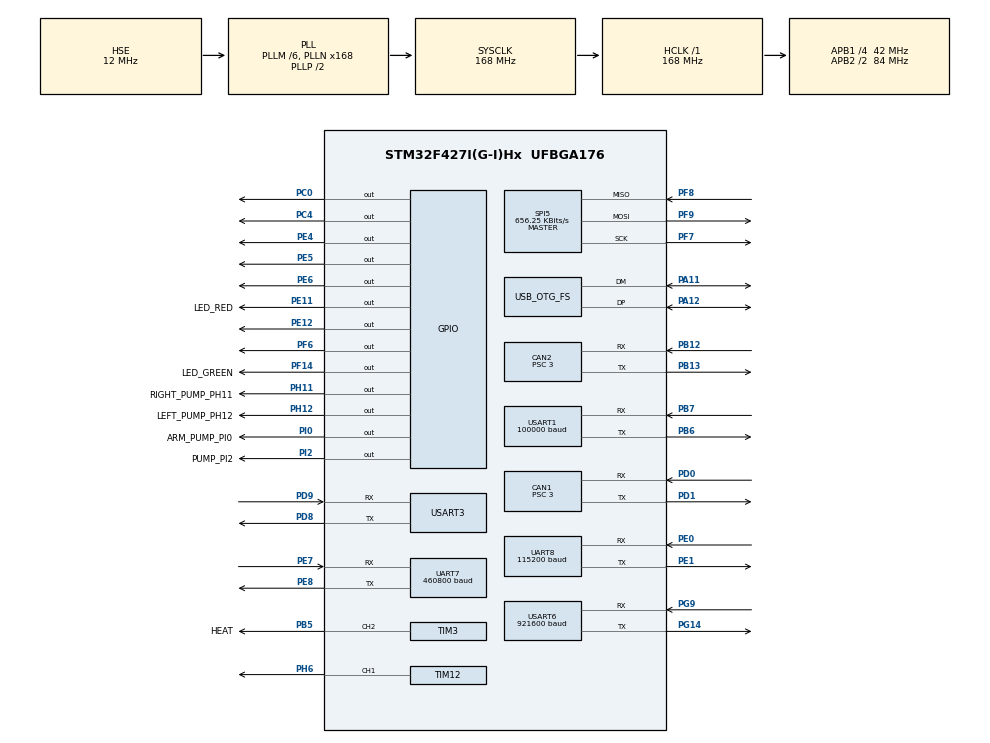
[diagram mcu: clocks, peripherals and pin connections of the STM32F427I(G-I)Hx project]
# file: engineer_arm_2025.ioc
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CAN1.ABOM=ENABLE
CAN1.AWUM=ENABLE
CAN1.BS1=CAN_BS1_7TQ
CAN1.BS2=CAN_BS2_6TQ
CAN1.CalculateBaudRate=1000000
CAN1.CalculateTimeBit=1000
CAN1.CalculateTimeQuantum=71.42857142857143
CAN1.NART=ENABLE
CAN1.Prescaler=3
CAN1.RFLM=DISABLE
CAN1.TXFP=ENABLE
CAN2.ABOM=ENABLE
CAN2.AWUM=ENABLE
CAN2.BS1=CAN_BS1_7TQ
CAN2.BS2=CAN_BS2_6TQ
CAN2.CalculateBaudRate=1000000
CAN2.CalculateTimeBit=1000
CAN2.CalculateTimeQuantum=71.42857142857143
CAN2.NART=ENABLE
CAN2.Prescaler=3
CAN2.TXFP=ENABLE
Dma.Request0=USART1_RX
Dma.Request1=SPI5_RX
Dma.Request2=SPI5_TX
Dma.Request3=UART8_RX
Dma.Request4=UART8_TX
Dma.Request5=USART3_RX
Dma.Request6=USART3_TX
Dma.Request7=UART7_RX
Dma.Request8=USART6_RX
Dma.Request9=USART6_TX
Dma.SPI5_RX.1.Direction=DMA_PERIPH_TO_MEMORY
Dma.SPI5_RX.1.FIFOMode=DMA_FIFOMODE_DISABLE
Dma.SPI5_RX.1.Instance=DMA2_Stream3
Dma.SPI5_RX.1.MemDataAlignment=DMA_MDATAALIGN_BYTE
Dma.SPI5_RX.1.MemInc=DMA_MINC_ENABLE
Dma.SPI5_RX.1.Mode=DMA_NORMAL
Dma.SPI5_RX.1.PeriphDataAlignment=DMA_PDATAALIGN_BYTE
Dma.SPI5_RX.1.PeriphInc=DMA_PINC_DISABLE
Dma.SPI5_RX.1.Priority=DMA_PRIORITY_HIGH
Dma.SPI5_TX.2.Direction=DMA_MEMORY_TO_PERIPH
Dma.SPI5_TX.2.FIFOMode=DMA_FIFOMODE_DISABLE
Dma.SPI5_TX.2.Instance=DMA2_Stream4
Dma.SPI5_TX.2.MemDataAlignment=DMA_MDATAALIGN_BYTE
Dma.SPI5_TX.2.MemInc=DMA_MINC_ENABLE
Dma.SPI5_TX.2.Mode=DMA_NORMAL
Dma.SPI5_TX.2.PeriphDataAlignment=DMA_PDATAALIGN_BYTE
Dma.SPI5_TX.2.PeriphInc=DMA_PINC_DISABLE
Dma.SPI5_TX.2.Priority=DMA_PRIORITY_HIGH
Dma.UART7_RX.7.Direction=DMA_PERIPH_TO_MEMORY
Dma.UART7_RX.7.FIFOMode=DMA_FIFOMODE_DISABLE
Dma.UART7_RX.7.Instance=DMA1_Stream3
Dma.UART7_RX.7.MemDataAlignment=DMA_MDATAALIGN_BYTE
Dma.UART7_RX.7.MemInc=DMA_MINC_ENABLE
Dma.UART7_RX.7.Mode=DMA_NORMAL
Dma.UART7_RX.7.PeriphDataAlignment=DMA_PDATAALIGN_BYTE
Dma.UART7_RX.7.PeriphInc=DMA_PINC_DISABLE
Dma.UART7_RX.7.Priority=DMA_PRIORITY_HIGH
Dma.UART8_RX.3.Direction=DMA_PERIPH_TO_MEMORY
Dma.UART8_RX.3.FIFOMode=DMA_FIFOMODE_DISABLE
Dma.UART8_RX.3.Instance=DMA1_Stream6
Dma.UART8_RX.3.MemDataAlignment=DMA_MDATAALIGN_BYTE
Dma.UART8_RX.3.MemInc=DMA_MINC_ENABLE
Dma.UART8_RX.3.Mode=DMA_CIRCULAR
Dma.UART8_RX.3.PeriphDataAlignment=DMA_PDATAALIGN_BYTE
Dma.UART8_RX.3.PeriphInc=DMA_PINC_DISABLE
Dma.UART8_RX.3.Priority=DMA_PRIORITY_HIGH
Dma.UART8_TX.4.Direction=DMA_MEMORY_TO_PERIPH
Dma.UART8_TX.4.FIFOMode=DMA_FIFOMODE_DISABLE
Dma.UART8_TX.4.Instance=DMA1_Stream0
Dma.UART8_TX.4.MemDataAlignment=DMA_MDATAALIGN_BYTE
Dma.UART8_TX.4.MemInc=DMA_MINC_ENABLE
Dma.UART8_TX.4.Mode=DMA_NORMAL
Dma.UART8_TX.4.PeriphDataAlignment=DMA_PDATAALIGN_BYTE
Dma.UART8_TX.4.PeriphInc=DMA_PINC_DISABLE
Dma.UART8_TX.4.Priority=DMA_PRIORITY_HIGH
Dma.USART1_RX.0.Direction=DMA_PERIPH_TO_MEMORY
Dma.USART1_RX.0.FIFOMode=DMA_FIFOMODE_DISABLE
Dma.USART1_RX.0.Instance=DMA2_Stream2
Dma.USART1_RX.0.MemDataAlignment=DMA_MDATAALIGN_BYTE
Dma.USART1_RX.0.MemInc=DMA_MINC_ENABLE
Dma.USART1_RX.0.Mode=DMA_NORMAL
Dma.USART1_RX.0.PeriphDataAlignment=DMA_PDATAALIGN_BYTE
Dma.USART1_RX.0.PeriphInc=DMA_PINC_DISABLE
Dma.USART1_RX.0.Priority=DMA_PRIORITY_HIGH
Dma.USART3_RX.5.Direction=DMA_PERIPH_TO_MEMORY
Dma.USART3_RX.5.FIFOMode=DMA_FIFOMODE_DISABLE
Dma.USART3_RX.5.Instance=DMA1_Stream1
Dma.USART3_RX.5.MemDataAlignment=DMA_MDATAALIGN_BYTE
Dma.USART3_RX.5.MemInc=DMA_MINC_ENABLE
Dma.USART3_RX.5.Mode=DMA_CIRCULAR
Dma.USART3_RX.5.PeriphDataAlignment=DMA_PDATAALIGN_BYTE
Dma.USART3_RX.5.PeriphInc=DMA_PINC_DISABLE
Dma.USART3_RX.5.Priority=DMA_PRIORITY_HIGH
Dma.USART3_TX.6.Direction=DMA_MEMORY_TO_PERIPH
Dma.USART3_TX.6.FIFOMode=DMA_FIFOMODE_DISABLE
Dma.USART3_TX.6.Instance=DMA1_Stream4
Dma.USART3_TX.6.MemDataAlignment=DMA_MDATAALIGN_BYTE
Dma.USART3_TX.6.MemInc=DMA_MINC_ENABLE
Dma.USART3_TX.6.Mode=DMA_NORMAL
Dma.USART3_TX.6.PeriphDataAlignment=DMA_PDATAALIGN_BYTE
Dma.USART3_TX.6.PeriphInc=DMA_PINC_DISABLE
Dma.USART3_TX.6.Priority=DMA_PRIORITY_HIGH
Dma.USART6_RX.8.Direction=DMA_PERIPH_TO_MEMORY
Dma.USART6_RX.8.FIFOMode=DMA_FIFOMODE_DISABLE
Dma.USART6_RX.8.Instance=DMA2_Stream1
Dma.USART6_RX.8.MemDataAlignment=DMA_MDATAALIGN_BYTE
Dma.USART6_RX.8.MemInc=DMA_MINC_ENABLE
Dma.USART6_RX.8.Mode=DMA_CIRCULAR
Dma.USART6_RX.8.PeriphDataAlignment=DMA_PDATAALIGN_BYTE
Dma.USART6_RX.8.PeriphInc=DMA_PINC_DISABLE
Dma.USART6_RX.8.Priority=DMA_PRIORITY_HIGH
Dma.USART6_TX.9.Direction=DMA_MEMORY_TO_PERIPH
Dma.USART6_TX.9.FIFOMode=DMA_FIFOMODE_DISABLE
Dma.USART6_TX.9.Instance=DMA2_Stream6
Dma.USART6_TX.9.MemDataAlignment=DMA_MDATAALIGN_BYTE
Dma.USART6_TX.9.MemInc=DMA_MINC_ENABLE
Dma.USART6_TX.9.Mode=DMA_NORMAL
Dma.USART6_TX.9.PeriphDataAlignment=DMA_PDATAALIGN_BYTE
Dma.USART6_TX.9.PeriphInc=DMA_PINC_DISABLE
Dma.USART6_TX.9.Priority=DMA_PRIORITY_HIGH
FREERTOS.BinarySemaphores01=ArmMotor1UpdateBinarySem,Dynamic,NULL,Depleted;ArmMotor2UpdateBinarySem,Dynamic,NULL,Depleted;ArmMotor3UpdateBinarySem,Dynamic,NULL,Depleted;ArmMotor4UpdateBinarySem,Dynamic,NULL,Depleted;ArmMotor5UpdateBinarySem,Dynamic,NULL,Depleted;ArmMotor6UpdateBinarySem,Dynamic,NULL,Depleted;RCUpdateBinarySem,Dynamic,NULL,Depleted;PCUpdateBinarySem,Dynamic,NULL,Depleted;CustomBinarySem,Dynamic,NULL,Depleted;judgementInitBinarySem,Dynamic,NULL,Depleted;customRxBinarySem,Dynamic,NULL,Depleted;CommunicateUpdateBinarySem,Dynamic,NULL,Depleted;IMUUpdateBinarySem,Dynamic,NULL,Depleted;servoctrlTxBinarySem,Dynamic,NULL,Available;hi229umRxBinarySem,Dynamic,NULL,Depleted;VTRCUpdateBinarySem,Dynamic,NULL,Depleted
FREERTOS.CountingSemaphores01=CAN1CountingSem,3,Dynamic,NULL,3;CAN2CountingSem,3,Dynamic,NULL,3
FREERTOS.Events01=refereeEvent,Dynamic,NULL;RefereeEvent,Dynamic,NULL
FREERTOS.INCLUDE_xEventGroupSetBitFromISR=1
FREERTOS.Queues01=CAN1SendQueue,32,can_device_transmit_member,0,Dynamic,NULL,NULL;CAN2SendQueue,16,can_device_transmit_member,0,Dynamic,NULL,NULL;ServoCtrlQueue,16,servo_ctrl_data_t,0,Dynamic,NULL,NULL
FREERTOS.Tasks01=defaultTask,24,128,StartDefaultTask,Default,NULL,Dynamic,NULL,NULL;CAN1SendTask,40,128,CAN1Send_Task,As weak,NULL,Dynamic,NULL,NULL;CAN2SendTask,40,128,CAN2Send_Task,As weak,NULL,Dynamic,NULL,NULL;armtask,24,512,arm_task,As weak,NULL,Dynamic,NULL,NULL;lostchecktask,24,512,lost_check_task,As weak,NULL,Dynamic,NULL,NULL;rctask,24,256,rc_task,As weak,NULL,Dynamic,NULL,NULL;pc_receivetask,47,1024,pc_receive_task,As weak,NULL,Dynamic,NULL,NULL;pc_transmittask,47,1024,pc_transmit_task,As weak,NULL,Dynamic,NULL,NULL;receiveCtrltask,24,256,receiveCtrl_task,As weak,NULL,Dynamic,NULL,NULL;updateUIDatatas,24,512,updateUIData_task,As weak,NULL,Dynamic,NULL,NULL;judgeCtrltask,24,256,judgeCtrl_task,As weak,NULL,Dynamic,NULL,NULL;controllertask,24,256,controller_task,As weak,NULL,Dynamic,NULL,NULL;imutask,24,256,imu_task,As weak,NULL,Dynamic,NULL,NULL;communicatetask,24,256,communicate_task,As weak,NULL,Dynamic,NULL,NULL;servo_ctrltask,24,128,servo_ctrl_task,As weak,NULL,Dynamic,NULL,NULL;gimbaltask,24,256,gimbal_task,As weak,NULL,Dynamic,NULL,NULL;hi229umtask,24,256,hi229um_task,As weak,NULL,Dynamic,NULL,NULL;arm_resettask,24,256,arm_reset_task,As weak,NULL,Dynamic,NULL,NULL;self_ctrltask,24,256,self_ctrl_task,As weak,NULL,Dynamic,NULL,NULL;self_kb_stateta,24,256,self_kb_state_task,As weak,NULL,Dynamic,NULL,NULL;self_kb_eventta,24,256,self_kb_event_task,As weak,NULL,Dynamic,NULL,NULL;VT_rctask,24,256,VT_rc_task,As weak,NULL,Dynamic,NULL,NULL
FREERTOS.configTOTAL_HEAP_SIZE=120000
FREERTOS.configUSE_NEWLIB_REENTRANT=1
IWDG.Prescaler=IWDG_PRESCALER_64
IWDG.Reload=625
Mcu.Family=STM32F4
Mcu.Name=STM32F427I(G-I)Hx
Mcu.Package=UFBGA176
NVIC.CAN1_RX0_IRQn=true\:5\:0\:false\:false\:true\:true\:true\:true\:true
NVIC.CAN1_TX_IRQn=true\:5\:0\:false\:false\:true\:true\:true\:true\:true
NVIC.CAN2_RX1_IRQn=true\:5\:0\:false\:false\:true\:true\:true\:true\:true
NVIC.CAN2_TX_IRQn=true\:5\:0\:false\:false\:true\:true\:true\:true\:true
NVIC.DMA1_Stream0_IRQn=true\:5\:0\:false\:false\:true\:true\:false\:true\:true
NVIC.DMA1_Stream1_IRQn=true\:5\:0\:false\:false\:true\:true\:false\:true\:true
NVIC.DMA1_Stream3_IRQn=true\:5\:0\:false\:false\:true\:true\:false\:true\:true
NVIC.DMA1_Stream4_IRQn=true\:5\:0\:false\:false\:true\:true\:false\:true\:true
NVIC.DMA1_Stream6_IRQn=true\:5\:0\:false\:false\:true\:true\:false\:true\:true
NVIC.DMA2_Stream1_IRQn=true\:5\:0\:false\:false\:true\:true\:false\:true\:true
NVIC.DMA2_Stream2_IRQn=true\:5\:0\:false\:false\:true\:true\:false\:true\:true
NVIC.DMA2_Stream3_IRQn=true\:5\:0\:false\:false\:true\:true\:false\:true\:true
NVIC.DMA2_Stream4_IRQn=true\:5\:0\:false\:false\:true\:true\:false\:true\:true
NVIC.DMA2_Stream6_IRQn=true\:5\:0\:false\:false\:true\:true\:false\:true\:true
NVIC.OTG_FS_IRQn=true\:5\:0\:false\:false\:true\:true\:true\:true\:true
NVIC.PriorityGroup=NVIC_PRIORITYGROUP_4
NVIC.SPI5_IRQn=true\:5\:0\:false\:false\:true\:true\:true\:true\:true
NVIC.TIM7_IRQn=true\:0\:0\:true\:false\:true\:false\:false\:true\:true
NVIC.TimeBase=TIM7_IRQn
NVIC.TimeBaseIP=TIM7
NVIC.UART7_IRQn=true\:5\:0\:false\:false\:true\:true\:true\:true\:true
NVIC.UART8_IRQn=true\:5\:0\:false\:false\:true\:true\:true\:true\:true
NVIC.USART1_IRQn=true\:5\:0\:false\:false\:true\:true\:true\:true\:true
NVIC.USART3_IRQn=true\:5\:0\:false\:false\:true\:true\:true\:true\:true
NVIC.USART6_IRQn=true\:5\:0\:false\:false\:true\:true\:true\:true\:true
PA11.Mode=Device_Only
PA11.Signal=USB_OTG_FS_DM
PA12.Mode=Device_Only
PA12.Signal=USB_OTG_FS_DP
PA13.Mode=Serial_Wire
PA13.Signal=SYS_JTMS-SWDIO
PA14.Mode=Serial_Wire
PA14.Signal=SYS_JTCK-SWCLK
PB12.Mode=CAN_Activate
PB12.Signal=CAN2_RX
PB13.Mode=CAN_Activate
PB13.Signal=CAN2_TX
PB5.GPIO_Label=HEAT
PB5.GPIO_PuPd=GPIO_PULLUP
PB5.GPIO_Speed=GPIO_SPEED_FREQ_HIGH
PB5.Signal=S_TIM3_CH2
PB6.Mode=Asynchronous
PB6.Signal=USART1_TX
PB7.Mode=Asynchronous
PB7.Signal=USART1_RX
PC0.GPIO_ModeDefaultOutputPP=GPIO_MODE_OUTPUT_OD
PC0.GPIO_PuPd=GPIO_PULLUP
PC0.GPIO_Speed=GPIO_SPEED_FREQ_HIGH
PC0.Signal=GPIO_Output
PC4.GPIO_ModeDefaultOutputPP=GPIO_MODE_OUTPUT_OD
PC4.GPIO_PuPd=GPIO_PULLUP
PC4.GPIO_Speed=GPIO_SPEED_FREQ_HIGH
PC4.Signal=GPIO_Output
PD0.Mode=CAN_Activate
PD0.Signal=CAN1_RX
PD1.Mode=CAN_Activate
PD1.Signal=CAN1_TX
PD8.Mode=Asynchronous
PD8.Signal=USART3_TX
PD9.Mode=Asynchronous
PD9.Signal=USART3_RX
PE0.Mode=Asynchronous
PE0.Signal=UART8_RX
PE1.Mode=Asynchronous
PE1.Signal=UART8_TX
PE11.GPIO_Label=LED_RED
PE11.PinState=GPIO_PIN_SET
PE11.Signal=GPIO_Output
PE12.GPIO_ModeDefaultOutputPP=GPIO_MODE_OUTPUT_OD
PE12.GPIO_PuPd=GPIO_PULLUP
PE12.GPIO_Speed=GPIO_SPEED_FREQ_HIGH
PE12.Signal=GPIO_Output
PE4.GPIO_ModeDefaultOutputPP=GPIO_MODE_OUTPUT_OD
PE4.GPIO_PuPd=GPIO_PULLUP
PE4.GPIO_Speed=GPIO_SPEED_FREQ_HIGH
PE4.Signal=GPIO_Output
PE5.GPIO_ModeDefaultOutputPP=GPIO_MODE_OUTPUT_OD
PE5.GPIO_PuPd=GPIO_PULLUP
PE5.GPIO_Speed=GPIO_SPEED_FREQ_HIGH
PE5.Signal=GPIO_Output
PE6.GPIO_ModeDefaultOutputPP=GPIO_MODE_OUTPUT_OD
PE6.GPIO_PuPd=GPIO_PULLUP
PE6.GPIO_Speed=GPIO_SPEED_FREQ_HIGH
PE6.Signal=GPIO_Output
PE7.Mode=Asynchronous
PE7.Signal=UART7_RX
PE8.Mode=Asynchronous
PE8.Signal=UART7_TX
PF14.GPIO_Label=LED_GREEN
PF14.PinState=GPIO_PIN_RESET
PF14.Signal=GPIO_Output
PF6.Signal=GPIO_Output
PF7.Mode=Full_Duplex_Master
PF7.Signal=SPI5_SCK
PF8.Mode=Full_Duplex_Master
PF8.Signal=SPI5_MISO
PF9.Mode=Full_Duplex_Master
PF9.Signal=SPI5_MOSI
PG14.Mode=Asynchronous
PG14.Signal=USART6_TX
PG9.Mode=Asynchronous
PG9.Signal=USART6_RX
PH0/OSC_IN.Mode=HSE-External-Oscillator
PH0/OSC_IN.Signal=RCC_OSC_IN
PH1/OSC_OUT.Mode=HSE-External-Oscillator
PH1/OSC_OUT.Signal=RCC_OSC_OUT
PH11.GPIO_Label=RIGHT_PUMP_PH11
PH11.GPIO_Speed=GPIO_SPEED_FREQ_HIGH
PH11.Signal=GPIO_Output
PH12.GPIO_Label=LEFT_PUMP_PH12
PH12.GPIO_Speed=GPIO_SPEED_FREQ_HIGH
PH12.Signal=GPIO_Output
PH6.Signal=S_TIM12_CH1
PI0.GPIO_Label=ARM_PUMP_PI0
PI0.PinState=GPIO_PIN_RESET
PI0.Signal=GPIO_Output
PI2.GPIO_Label=PUMP_PI2
PI2.PinState=GPIO_PIN_RESET
PI2.Signal=GPIO_Output
ProjectManager.HeapSize=0x1000
ProjectManager.StackSize=0x1000
ProjectManager.TargetToolchain=STM32CubeIDE
RCC.48MHZClocksFreq_Value=48000000
RCC.AHBFreq_Value=168000000
RCC.APB1CLKDivider=RCC_HCLK_DIV4
RCC.APB1Freq_Value=42000000
RCC.APB1TimFreq_Value=84000000
RCC.APB2CLKDivider=RCC_HCLK_DIV2
RCC.APB2Freq_Value=84000000
RCC.APB2TimFreq_Value=168000000
RCC.CortexFreq_Value=168000000
RCC.HCLKFreq_Value=168000000
RCC.HSE_VALUE=12000000
RCC.HSI_VALUE=16000000
RCC.LSE_VALUE=32768
RCC.PLLM=6
RCC.PLLN=168
RCC.PLLQ=7
RCC.SYSCLKFreq_VALUE=168000000
RCC.SYSCLKSource=RCC_SYSCLKSOURCE_PLLCLK
RCC.VCOOutputFreq_Value=336000000
SH.S_TIM12_CH1.0=TIM12_CH1,PWM Generation1 CH1
SH.S_TIM3_CH2.0=TIM3_CH2,PWM Generation2 CH2
SPI5.BaudRatePrescaler=SPI_BAUDRATEPRESCALER_128
SPI5.CalculateBaudRate=656.25 KBits/s
SPI5.Direction=SPI_DIRECTION_2LINES
SPI5.Mode=SPI_MODE_MASTER
SPI5.VirtualType=VM_MASTER
STMicroelectronics.X-CUBE-ALGOBUILD.1.3.0.LibraryCcDSPOoLibraryJjDSPOoLibrary=true
TIM12.Channel-PWM\ Generation1\ CH1=TIM_CHANNEL_1
TIM12.Period=370-1
TIM12.Prescaler=84-1
TIM3.Channel-PWM\ Generation2\ CH2=TIM_CHANNEL_2
TIM3.Period=9999
UART7.BaudRate=460800
UART7.VirtualMode=Asynchronous
UART8.BaudRate=115200
UART8.VirtualMode=Asynchronous
UART8.WordLength=WORDLENGTH_8B
USART1.BaudRate=100000
USART1.Parity=PARITY_EVEN
USART1.VirtualMode=VM_ASYNC
USART1.WordLength=WORDLENGTH_9B
USART3.VirtualMode=VM_ASYNC
USART3.WordLength=WORDLENGTH_8B
USART6.BaudRate=921600
USART6.VirtualMode=VM_ASYNC
USB_DEVICE.APP_RX_DATA_SIZE-CDC_FS=2048
USB_DEVICE.APP_TX_DATA_SIZE-CDC_FS=2048
USB_DEVICE.CLASS_NAME_FS=CDC
USB_DEVICE.VirtualMode-CDC_FS=Cdc
USB_DEVICE.VirtualModeFS=Cdc_FS
USB_OTG_FS.VirtualMode=Device_Only
VP_FREERTOS_VS_CMSIS_V2.Mode=CMSIS_V2
VP_IWDG_VS_IWDG.Mode=IWDG_Activate
VP_STMicroelectronics.X-CUBE-ALGOBUILD_VS_DSPOoLibraryJjLibrary_1.3.0_1.3.0.Mode=DSPOoLibraryJjLibrary
VP_SYS_VS_tim7.Mode=TIM7
VP_TIM12_VS_ClockSourceINT.Mode=Internal
VP_TIM3_VS_ClockSourceINT.Mode=Internal
VP_USB_DEVICE_VS_USB_DEVICE_CDC_FS.Mode=CDC_FS
board=custom

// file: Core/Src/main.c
/* USER CODE BEGIN Header */
/**
  ******************************************************************************
  * @file           : main.c
  * @brief          : Main program body
  ******************************************************************************
  * @attention
  *
  * Copyright (c) 2025 STMicroelectronics.
  * All rights reserved.
  *
  * This software is licensed under terms that can be found in the LICENSE file
  * in the root directory of this software component.
  * If no LICENSE file comes with this software, it is provided AS-IS.
  *
  ******************************************************************************
  */
/* USER CODE END Header */
#include "main.h"
#include "cmsis_os.h"
#include "can.h"
#include "dma.h"
#include "iwdg.h"
#include "spi.h"
#include "tim.h"
#include "usart.h"
#include "usb_device.h"
#include "gpio.h"

/* USER CODE BEGIN Includes */
#include "compatible.h"
#include "bsp_dwt.h"
/* USER CODE END Includes */

void SystemClock_Config(void);
void MX_FREERTOS_Init(void);

int main(void)
{

  /* USER CODE BEGIN 1 */
    __HAL_RCC_SYSCLK_CONFIG(RCC_SYSCLKSOURCE_HSI);
  /* USER CODE END 1 */

  /* MCU Configuration--------------------------------------------------------*/

  /* Reset of all peripherals, Initializes the Flash interface and the Systick. */
  HAL_Init();

  /* Configure the system clock */
  SystemClock_Config();

  /* Initialize all configured peripherals */
  MX_GPIO_Init();
  MX_DMA_Init();
  MX_SPI5_Init();
  MX_USART1_UART_Init();
  MX_CAN1_Init();
  MX_CAN2_Init();
  MX_TIM12_Init();
  MX_UART8_Init();
  MX_TIM3_Init();
  MX_USART3_UART_Init();
  MX_UART7_Init();
  MX_USART6_UART_Init();
  MX_IWDG_Init();
  /* USER CODE BEGIN 2 */
    DWT_Init(168);
    bsp_can_init();
  /* USER CODE END 2 */

  /* Init scheduler */
  osKernelInitialize();

  /* Call init function for freertos objects (in cmsis_os2.c) */
  MX_FREERTOS_Init();

  /* Start scheduler */
  osKernelStart();

  /* We should never get here as control is now taken by the scheduler */

  /* Infinite loop */
  while (1)
  {

  }
}

void SystemClock_Config(void)
{
  RCC_OscInitTypeDef RCC_OscInitStruct = {0};
  RCC_ClkInitTypeDef RCC_ClkInitStruct = {0};

  /** Configure the main internal regulator output voltage
  */
  __HAL_RCC_PWR_CLK_ENABLE();
  __HAL_PWR_VOLTAGESCALING_CONFIG(PWR_REGULATOR_VOLTAGE_SCALE1);

  /** Initializes the RCC Oscillators according to the specified parameters
  * in the RCC_OscInitTypeDef structure.
  */
  RCC_OscInitStruct.OscillatorType = RCC_OSCILLATORTYPE_LSI|RCC_OSCILLATORTYPE_HSE;
  RCC_OscInitStruct.HSEState = RCC_HSE_ON;
  RCC_OscInitStruct.LSIState = RCC_LSI_ON;
  RCC_OscInitStruct.PLL.PLLState = RCC_PLL_ON;
  RCC_OscInitStruct.PLL.PLLSource = RCC_PLLSOURCE_HSE;
  RCC_OscInitStruct.PLL.PLLM = 6;
  RCC_OscInitStruct.PLL.PLLN = 168;
  RCC_OscInitStruct.PLL.PLLP = RCC_PLLP_DIV2;
  RCC_OscInitStruct.PLL.PLLQ = 7;
  if (HAL_RCC_OscConfig(&RCC_OscInitStruct) != HAL_OK)
  {
    Error_Handler();
  }

  /** Initializes the CPU, AHB and APB buses clocks
  */
  RCC_ClkInitStruct.ClockType = RCC_CLOCKTYPE_HCLK|RCC_CLOCKTYPE_SYSCLK
                              |RCC_CLOCKTYPE_PCLK1|RCC_CLOCKTYPE_PCLK2;
  RCC_ClkInitStruct.SYSCLKSource = RCC_SYSCLKSOURCE_PLLCLK;
  RCC_ClkInitStruct.AHBCLKDivider = RCC_SYSCLK_DIV1;
  RCC_ClkInitStruct.APB1CLKDivider = RCC_HCLK_DIV4;
  RCC_ClkInitStruct.APB2CLKDivider = RCC_HCLK_DIV2;

  if (HAL_RCC_ClockConfig(&RCC_ClkInitStruct, FLASH_LATENCY_5) != HAL_OK)
  {
    Error_Handler();
  }
}

void HAL_TIM_PeriodElapsedCallback(TIM_HandleTypeDef *htim)
{
  if (htim->Instance == TIM7)
  {
    HAL_IncTick();
  }
}

void Error_Handler(void)
{
  __disable_irq();
  while (1)
  {
  }
}

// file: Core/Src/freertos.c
/* USER CODE BEGIN Header */
/**
  ******************************************************************************
  * File Name          : freertos.c
  * Description        : Code for freertos applications
  ******************************************************************************
  * @attention
  *
  * Copyright (c) 2025 STMicroelectronics.
  * All rights reserved.
  *
  * This software is licensed under terms that can be found in the LICENSE file
  * in the root directory of this software component.
  * If no LICENSE file comes with this software, it is provided AS-IS.
  *
  ******************************************************************************
  */
/* USER CODE END Header */

#include "FreeRTOS.h"
#include "task.h"
#include "main.h"
#include "cmsis_os.h"

/* USER CODE BEGIN Includes */
#include "compatible.h"
/* USER CODE END Includes */

/* USER CODE BEGIN Variables */
extern IWDG_HandleTypeDef hiwdg;

/* USER CODE END Variables */
/* Definitions for defaultTask */
osThreadId_t defaultTaskHandle;
const osThreadAttr_t defaultTask_attributes = {
  .name = "defaultTask",
  .stack_size = 128 * 4,
  .priority = (osPriority_t) osPriorityNormal,
};
/* Definitions for CAN1SendTask */
osThreadId_t CAN1SendTaskHandle;
const osThreadAttr_t CAN1SendTask_attributes = {
  .name = "CAN1SendTask",
  .stack_size = 128 * 4,
  .priority = (osPriority_t) osPriorityHigh,
};
/* Definitions for CAN2SendTask */
osThreadId_t CAN2SendTaskHandle;
const osThreadAttr_t CAN2SendTask_attributes = {
  .name = "CAN2SendTask",
  .stack_size = 128 * 4,
  .priority = (osPriority_t) osPriorityHigh,
};
/* Definitions for armtask */
osThreadId_t armtaskHandle;
const osThreadAttr_t armtask_attributes = {
  .name = "armtask",
  .stack_size = 512 * 4,
  .priority = (osPriority_t) osPriorityNormal,
};
/* Definitions for lostchecktask */
osThreadId_t lostchecktaskHandle;
const osThreadAttr_t lostchecktask_attributes = {
  .name = "lostchecktask",
  .stack_size = 512 * 4,
  .priority = (osPriority_t) osPriorityNormal,
};
/* Definitions for rctask */
osThreadId_t rctaskHandle;
const osThreadAttr_t rctask_attributes = {
  .name = "rctask",
  .stack_size = 256 * 4,
  .priority = (osPriority_t) osPriorityNormal,
};
/* Definitions for pc_receivetask */
osThreadId_t pc_receivetaskHandle;
const osThreadAttr_t pc_receivetask_attributes = {
  .name = "pc_receivetask",
  .stack_size = 1024 * 4,
  .priority = (osPriority_t) osPriorityHigh7,
};
/* Definitions for pc_transmittask */
osThreadId_t pc_transmittaskHandle;
const osThreadAttr_t pc_transmittask_attributes = {
  .name = "pc_transmittask",
  .stack_size = 1024 * 4,
  .priority = (osPriority_t) osPriorityHigh7,
};
/* Definitions for receiveCtrltask */
osThreadId_t receiveCtrltaskHandle;
const osThreadAttr_t receiveCtrltask_attributes = {
  .name = "receiveCtrltask",
  .stack_size = 256 * 4,
  .priority = (osPriority_t) osPriorityNormal,
};
/* Definitions for updateUIDatatas */
osThreadId_t updateUIDatatasHandle;
const osThreadAttr_t updateUIDatatas_attributes = {
  .name = "updateUIDatatas",
  .stack_size = 512 * 4,
  .priority = (osPriority_t) osPriorityNormal,
};
/* Definitions for judgeCtrltask */
osThreadId_t judgeCtrltaskHandle;
const osThreadAttr_t judgeCtrltask_attributes = {
  .name = "judgeCtrltask",
  .stack_size = 256 * 4,
  .priority = (osPriority_t) osPriorityNormal,
};
/* Definitions for controllertask */
osThreadId_t controllertaskHandle;
const osThreadAttr_t controllertask_attributes = {
  .name = "controllertask",
  .stack_size = 256 * 4,
  .priority = (osPriority_t) osPriorityNormal,
};
/* Definitions for imutask */
osThreadId_t imutaskHandle;
const osThreadAttr_t imutask_attributes = {
  .name = "imutask",
  .stack_size = 256 * 4,
  .priority = (osPriority_t) osPriorityNormal,
};
/* Definitions for communicatetask */
osThreadId_t communicatetaskHandle;
const osThreadAttr_t communicatetask_attributes = {
  .name = "communicatetask",
  .stack_size = 256 * 4,
  .priority = (osPriority_t) osPriorityNormal,
};
/* Definitions for servo_ctrltask */
osThreadId_t servo_ctrltaskHandle;
const osThreadAttr_t servo_ctrltask_attributes = {
  .name = "servo_ctrltask",
  .stack_size = 128 * 4,
  .priority = (osPriority_t) osPriorityNormal,
};
/* Definitions for gimbaltask */
osThreadId_t gimbaltaskHandle;
const osThreadAttr_t gimbaltask_attributes = {
  .name = "gimbaltask",
  .stack_size = 256 * 4,
  .priority = (osPriority_t) osPriorityNormal,
};
/* Definitions for hi229umtask */
osThreadId_t hi229umtaskHandle;
const osThreadAttr_t hi229umtask_attributes = {
  .name = "hi229umtask",
  .stack_size = 256 * 4,
  .priority = (osPriority_t) osPriorityNormal,
};
/* Definitions for arm_resettask */
osThreadId_t arm_resettaskHandle;
const osThreadAttr_t arm_resettask_attributes = {
  .name = "arm_resettask",
  .stack_size = 256 * 4,
  .priority = (osPriority_t) osPriorityNormal,
};
/* Definitions for self_ctrltask */
osThreadId_t self_ctrltaskHandle;
const osThreadAttr_t self_ctrltask_attributes = {
  .name = "self_ctrltask",
  .stack_size = 256 * 4,
  .priority = (osPriority_t) osPriorityNormal,
};
/* Definitions for self_kb_stateta */
osThreadId_t self_kb_statetaHandle;
const osThreadAttr_t self_kb_stateta_attributes = {
  .name = "self_kb_stateta",
  .stack_size = 256 * 4,
  .priority = (osPriority_t) osPriorityNormal,
};
/* Definitions for self_kb_eventta */
osThreadId_t self_kb_eventtaHandle;
const osThreadAttr_t self_kb_eventta_attributes = {
  .name = "self_kb_eventta",
  .stack_size = 256 * 4,
  .priority = (osPriority_t) osPriorityNormal,
};
/* Definitions for VT_rctask */
osThreadId_t VT_rctaskHandle;
const osThreadAttr_t VT_rctask_attributes = {
  .name = "VT_rctask",
  .stack_size = 256 * 4,
  .priority = (osPriority_t) osPriorityNormal,
};
/* Definitions for CAN1SendQueue */
osMessageQueueId_t CAN1SendQueueHandle;
const osMessageQueueAttr_t CAN1SendQueue_attributes = {
  .name = "CAN1SendQueue"
};
/* Definitions for CAN2SendQueue */
osMessageQueueId_t CAN2SendQueueHandle;
const osMessageQueueAttr_t CAN2SendQueue_attributes = {
  .name = "CAN2SendQueue"
};
/* Definitions for ServoCtrlQueue */
osMessageQueueId_t ServoCtrlQueueHandle;
const osMessageQueueAttr_t ServoCtrlQueue_attributes = {
  .name = "ServoCtrlQueue"
};
/* Definitions for ArmMotor1UpdateBinarySem */
osSemaphoreId_t ArmMotor1UpdateBinarySemHandle;
const osSemaphoreAttr_t ArmMotor1UpdateBinarySem_attributes = {
  .name = "ArmMotor1UpdateBinarySem"
};
/* Definitions for ArmMotor2UpdateBinarySem */
osSemaphoreId_t ArmMotor2UpdateBinarySemHandle;
const osSemaphoreAttr_t ArmMotor2UpdateBinarySem_attributes = {
  .name = "ArmMotor2UpdateBinarySem"
};
/* Definitions for ArmMotor3UpdateBinarySem */
osSemaphoreId_t ArmMotor3UpdateBinarySemHandle;
const osSemaphoreAttr_t ArmMotor3UpdateBinarySem_attributes = {
  .name = "ArmMotor3UpdateBinarySem"
};
/* Definitions for ArmMotor4UpdateBinarySem */
osSemaphoreId_t ArmMotor4UpdateBinarySemHandle;
const osSemaphoreAttr_t ArmMotor4UpdateBinarySem_attributes = {
  .name = "ArmMotor4UpdateBinarySem"
};
/* Definitions for ArmMotor5UpdateBinarySem */
osSemaphoreId_t ArmMotor5UpdateBinarySemHandle;
const osSemaphoreAttr_t ArmMotor5UpdateBinarySem_attributes = {
  .name = "ArmMotor5UpdateBinarySem"
};
/* Definitions for ArmMotor6UpdateBinarySem */
osSemaphoreId_t ArmMotor6UpdateBinarySemHandle;
const osSemaphoreAttr_t ArmMotor6UpdateBinarySem_attributes = {
  .name = "ArmMotor6UpdateBinarySem"
};
/* Definitions for RCUpdateBinarySem */
osSemaphoreId_t RCUpdateBinarySemHandle;
const osSemaphoreAttr_t RCUpdateBinarySem_attributes = {
  .name = "RCUpdateBinarySem"
};
/* Definitions for PCUpdateBinarySem */
osSemaphoreId_t PCUpdateBinarySemHandle;
const osSemaphoreAttr_t PCUpdateBinarySem_attributes = {
  .name = "PCUpdateBinarySem"
};
/* Definitions for CustomBinarySem */
osSemaphoreId_t CustomBinarySemHandle;
const osSemaphoreAttr_t CustomBinarySem_attributes = {
  .name = "CustomBinarySem"
};
/* Definitions for judgementInitBinarySem */
osSemaphoreId_t judgementInitBinarySemHandle;
const osSemaphoreAttr_t judgementInitBinarySem_attributes = {
  .name = "judgementInitBinarySem"
};
/* Definitions for customRxBinarySem */
osSemaphoreId_t customRxBinarySemHandle;
const osSemaphoreAttr_t customRxBinarySem_attributes = {
  .name = "customRxBinarySem"
};
/* Definitions for CommunicateUpdateBinarySem */
osSemaphoreId_t CommunicateUpdateBinarySemHandle;
const osSemaphoreAttr_t CommunicateUpdateBinarySem_attributes = {
  .name = "CommunicateUpdateBinarySem"
};
/* Definitions for IMUUpdateBinarySem */
osSemaphoreId_t IMUUpdateBinarySemHandle;
const osSemaphoreAttr_t IMUUpdateBinarySem_attributes = {
  .name = "IMUUpdateBinarySem"
};
/* Definitions for servoctrlTxBinarySem */
osSemaphoreId_t servoctrlTxBinarySemHandle;
const osSemaphoreAttr_t servoctrlTxBinarySem_attributes = {
  .name = "servoctrlTxBinarySem"
};
/* Definitions for hi229umRxBinarySem */
osSemaphoreId_t hi229umRxBinarySemHandle;
const osSemaphoreAttr_t hi229umRxBinarySem_attributes = {
  .name = "hi229umRxBinarySem"
};
/* Definitions for VTRCUpdateBinarySem */
osSemaphoreId_t VTRCUpdateBinarySemHandle;
const osSemaphoreAttr_t VTRCUpdateBinarySem_attributes = {
  .name = "VTRCUpdateBinarySem"
};
/* Definitions for CAN1CountingSem */
osSemaphoreId_t CAN1CountingSemHandle;
const osSemaphoreAttr_t CAN1CountingSem_attributes = {
  .name = "CAN1CountingSem"
};
/* Definitions for CAN2CountingSem */
osSemaphoreId_t CAN2CountingSemHandle;
const osSemaphoreAttr_t CAN2CountingSem_attributes = {
  .name = "CAN2CountingSem"
};
/* Definitions for refereeEvent */
osEventFlagsId_t refereeEventHandle;
const osEventFlagsAttr_t refereeEvent_attributes = {
  .name = "refereeEvent"
};
/* Definitions for RefereeEvent */
osEventFlagsId_t RefereeEventHandle;
const osEventFlagsAttr_t RefereeEvent_attributes = {
  .name = "RefereeEvent"
};

void StartDefaultTask(void *argument);
void CAN1Send_Task(void *argument);
void CAN2Send_Task(void *argument);
void arm_task(void *argument);
void lost_check_task(void *argument);
void rc_task(void *argument);
void pc_receive_task(void *argument);
void pc_transmit_task(void *argument);
void receiveCtrl_task(void *argument);
void updateUIData_task(void *argument);
void judgeCtrl_task(void *argument);
void controller_task(void *argument);
void imu_task(void *argument);
void communicate_task(void *argument);
void servo_ctrl_task(void *argument);
void gimbal_task(void *argument);
void hi229um_task(void *argument);
void arm_reset_task(void *argument);
void self_ctrl_task(void *argument);
void self_kb_state_task(void *argument);
void self_kb_event_task(void *argument);
void VT_rc_task(void *argument);

extern void MX_USB_DEVICE_Init(void);
void MX_FREERTOS_Init(void); /* (MISRA C 2004 rule 8.1) */

void MX_FREERTOS_Init(void) {

  /* Create the semaphores(s) */
  /* creation of ArmMotor1UpdateBinarySem */
  ArmMotor1UpdateBinarySemHandle = osSemaphoreNew(1, 0, &ArmMotor1UpdateBinarySem_attributes);

  /* creation of ArmMotor2UpdateBinarySem */
  ArmMotor2UpdateBinarySemHandle = osSemaphoreNew(1, 0, &ArmMotor2UpdateBinarySem_attributes);

  /* creation of ArmMotor3UpdateBinarySem */
  ArmMotor3UpdateBinarySemHandle = osSemaphoreNew(1, 0, &ArmMotor3UpdateBinarySem_attributes);

  /* creation of ArmMotor4UpdateBinarySem */
  ArmMotor4UpdateBinarySemHandle = osSemaphoreNew(1, 0, &ArmMotor4UpdateBinarySem_attributes);

  /* creation of ArmMotor5UpdateBinarySem */
  ArmMotor5UpdateBinarySemHandle = osSemaphoreNew(1, 0, &ArmMotor5UpdateBinarySem_attributes);

  /* creation of ArmMotor6UpdateBinarySem */
  ArmMotor6UpdateBinarySemHandle = osSemaphoreNew(1, 0, &ArmMotor6UpdateBinarySem_attributes);

  /* creation of RCUpdateBinarySem */
  RCUpdateBinarySemHandle = osSemaphoreNew(1, 0, &RCUpdateBinarySem_attributes);

  /* creation of PCUpdateBinarySem */
  PCUpdateBinarySemHandle = osSemaphoreNew(1, 0, &PCUpdateBinarySem_attributes);

  /* creation of CustomBinarySem */
  CustomBinarySemHandle = osSemaphoreNew(1, 0, &CustomBinarySem_attributes);

  /* creation of judgementInitBinarySem */
  judgementInitBinarySemHandle = osSemaphoreNew(1, 0, &judgementInitBinarySem_attributes);

  /* creation of customRxBinarySem */
  customRxBinarySemHandle = osSemaphoreNew(1, 0, &customRxBinarySem_attributes);

  /* creation of CommunicateUpdateBinarySem */
  CommunicateUpdateBinarySemHandle = osSemaphoreNew(1, 0, &CommunicateUpdateBinarySem_attributes);

  /* creation of IMUUpdateBinarySem */
  IMUUpdateBinarySemHandle = osSemaphoreNew(1, 0, &IMUUpdateBinarySem_attributes);

  /* creation of servoctrlTxBinarySem */
  servoctrlTxBinarySemHandle = osSemaphoreNew(1, 1, &servoctrlTxBinarySem_attributes);

  /* creation of hi229umRxBinarySem */
  hi229umRxBinarySemHandle = osSemaphoreNew(1, 0, &hi229umRxBinarySem_attributes);

  /* creation of VTRCUpdateBinarySem */
  VTRCUpdateBinarySemHandle = osSemaphoreNew(1, 0, &VTRCUpdateBinarySem_attributes);

  /* creation of CAN1CountingSem */
  CAN1CountingSemHandle = osSemaphoreNew(3, 3, &CAN1CountingSem_attributes);

  /* creation of CAN2CountingSem */
  CAN2CountingSemHandle = osSemaphoreNew(3, 3, &CAN2CountingSem_attributes);

  /* Create the queue(s) */
  /* creation of CAN1SendQueue */
  CAN1SendQueueHandle = osMessageQueueNew (32, sizeof(can_device_transmit_member), &CAN1SendQueue_attributes);

  /* creation of CAN2SendQueue */
  CAN2SendQueueHandle = osMessageQueueNew (16, sizeof(can_device_transmit_member), &CAN2SendQueue_attributes);

  /* creation of ServoCtrlQueue */
  ServoCtrlQueueHandle = osMessageQueueNew (16, sizeof(servo_ctrl_data_t), &ServoCtrlQueue_attributes);

  /* Create the thread(s) */
  /* creation of defaultTask */
  defaultTaskHandle = osThreadNew(StartDefaultTask, NULL, &defaultTask_attributes);

  /* creation of CAN1SendTask */
  CAN1SendTaskHandle = osThreadNew(CAN1Send_Task, NULL, &CAN1SendTask_attributes);

  /* creation of CAN2SendTask */
  CAN2SendTaskHandle = osThreadNew(CAN2Send_Task, NULL, &CAN2SendTask_attributes);

  /* creation of armtask */
  armtaskHandle = osThreadNew(arm_task, NULL, &armtask_attributes);

  /* creation of lostchecktask */
  lostchecktaskHandle = osThreadNew(lost_check_task, NULL, &lostchecktask_attributes);

  /* creation of rctask */
  rctaskHandle = osThreadNew(rc_task, NULL, &rctask_attributes);

  /* creation of pc_receivetask */
  pc_receivetaskHandle = osThreadNew(pc_receive_task, NULL, &pc_receivetask_attributes);

  /* creation of pc_transmittask */
  pc_transmittaskHandle = osThreadNew(pc_transmit_task, NULL, &pc_transmittask_attributes);

  /* creation of receiveCtrltask */
  receiveCtrltaskHandle = osThreadNew(receiveCtrl_task, NULL, &receiveCtrltask_attributes);

  /* creation of updateUIDatatas */
  updateUIDatatasHandle = osThreadNew(updateUIData_task, NULL, &updateUIDatatas_attributes);

  /* creation of judgeCtrltask */
  judgeCtrltaskHandle = osThreadNew(judgeCtrl_task, NULL, &judgeCtrltask_attributes);

  /* creation of controllertask */
  controllertaskHandle = osThreadNew(controller_task, NULL, &controllertask_attributes);

  /* creation of imutask */
  imutaskHandle = osThreadNew(imu_task, NULL, &imutask_attributes);

  /* creation of communicatetask */
  communicatetaskHandle = osThreadNew(communicate_task, NULL, &communicatetask_attributes);

  /* creation of servo_ctrltask */
  servo_ctrltaskHandle = osThreadNew(servo_ctrl_task, NULL, &servo_ctrltask_attributes);

  /* creation of gimbaltask */
  gimbaltaskHandle = osThreadNew(gimbal_task, NULL, &gimbaltask_attributes);

  /* creation of hi229umtask */
  hi229umtaskHandle = osThreadNew(hi229um_task, NULL, &hi229umtask_attributes);

  /* creation of arm_resettask */
  arm_resettaskHandle = osThreadNew(arm_reset_task, NULL, &arm_resettask_attributes);

  /* creation of self_ctrltask */
  self_ctrltaskHandle = osThreadNew(self_ctrl_task, NULL, &self_ctrltask_attributes);

  /* creation of self_kb_stateta */
  self_kb_statetaHandle = osThreadNew(self_kb_state_task, NULL, &self_kb_stateta_attributes);

  /* creation of self_kb_eventta */
  self_kb_eventtaHandle = osThreadNew(self_kb_event_task, NULL, &self_kb_eventta_attributes);

  /* creation of VT_rctask */
  VT_rctaskHandle = osThreadNew(VT_rc_task, NULL, &VT_rctask_attributes);

  /* Create the event(s) */
  /* creation of refereeEvent */
  refereeEventHandle = osEventFlagsNew(&refereeEvent_attributes);

  /* creation of RefereeEvent */
  RefereeEventHandle = osEventFlagsNew(&RefereeEvent_attributes);

}

void StartDefaultTask(void *argument)
{
  /* init code for USB_DEVICE */
  MX_USB_DEVICE_Init();
  /* USER CODE BEGIN StartDefaultTask */
  /* Infinite loop */
  for(;;)
  {
      HAL_IWDG_Refresh(&hiwdg);
      HAL_GPIO_TogglePin(LED_GREEN_GPIO_Port,LED_GREEN_Pin);
      osDelay(500);  }
  /* USER CODE END StartDefaultTask */
}

__weak void CAN1Send_Task(void *argument)
{
  for(;;)
  {
    osDelay(1);
  }
}

__weak void CAN2Send_Task(void *argument)
{
  for(;;)
  {
    osDelay(1);
  }
}

__weak void arm_task(void *argument)
{
  for(;;)
  {
    osDelay(1);
  }
}

__weak void lost_check_task(void *argument)
{
  for(;;)
  {
    osDelay(1);
  }
}

__weak void rc_task(void *argument)
{
  for(;;)
  {
    osDelay(1);
  }
}

__weak void pc_receive_task(void *argument)
{
  for(;;)
  {
    osDelay(1);
  }
}

__weak void pc_transmit_task(void *argument)
{
  for(;;)
  {
    osDelay(1);
  }
}

__weak void receiveCtrl_task(void *argument)
{
  for(;;)
  {
    osDelay(1);
  }
}

__weak void updateUIData_task(void *argument)
{
  for(;;)
  {
    osDelay(1);
  }
}

__weak void judgeCtrl_task(void *argument)
{
  for(;;)
  {
    osDelay(1);
  }
}

__weak void controller_task(void *argument)
{
  for(;;)
  {
    osDelay(1);
  }
}

__weak void imu_task(void *argument)
{
  for(;;)
  {
    osDelay(1);
  }
}

__weak void communicate_task(void *argument)
{
  for(;;)
  {
    osDelay(1);
  }
}

__weak void servo_ctrl_task(void *argument)
{
  for(;;)
  {
    osDelay(1);
  }
}

__weak void gimbal_task(void *argument)
{
  for(;;)
  {
    osDelay(1);
  }
}

__weak void hi229um_task(void *argument)
{
  for(;;)
  {
    osDelay(1);
  }
}

__weak void arm_reset_task(void *argument)
{
  for(;;)
  {
    osDelay(1);
  }
}

__weak void self_ctrl_task(void *argument)
{
  for(;;)
  {
    osDelay(1);
  }
}

__weak void self_kb_state_task(void *argument)
{
  for(;;)
  {
    osDelay(1);
  }
}

__weak void self_kb_event_task(void *argument)
{
  for(;;)
  {
    osDelay(1);
  }
}

__weak void VT_rc_task(void *argument)
{
  for(;;)
  {
    osDelay(1);
  }
}
